AUTOSAR XML (schema 00048)
package /AUTOLIV/SoftwareComponents/BFE
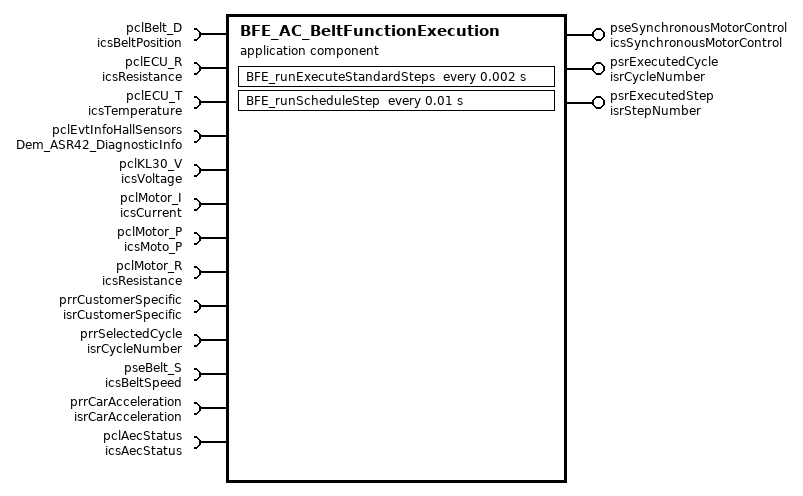
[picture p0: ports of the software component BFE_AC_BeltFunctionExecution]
  application sw component type BFE_AC_BeltFunctionExecution
    11 x require port:
      pclBelt_D: required-com-specs=[GetFromMinPos_deg, GetFromMinPos_mm, GetFromT0_deg, GetFromT0_mm, GetRange_deg, GetRange_mm], required-interface=icsBeltPosition
      pclECU_R: client-com-spec=Get, required-interface=icsResistance
      pclECU_T: required-com-specs=[GetFiltered, GetFiltered_deg, Init], required-interface=icsTemperature
      pclEvtInfoHallSensors: required-interface=Dem_ASR42_DiagnosticInfo
        required-com-specs:
          GetDTCOfEvent
          GetDebouncingOfEvent
          GetEventExtendedDataRecord
          GetEventExtendedDataRecordEx
          GetEventFailed
          GetEventFreezeFrameData
          GetEventFreezeFrameDataEx
          GetEventStatus
          GetEventTested
          GetFaultDetectionCounter
      pclKL30_V: required-com-specs=[Get, Get_100ms, Get_10ms, Get_20ms, Get_2ms], required-interface=icsVoltage
      pclMotor_I: required-com-specs=[ConvertCurrent_mAtoLSB, Get_A, Get_LSB, Get_mA], required-interface=icsCurrent
      pclMotor_P: required-com-specs=[GetPowerOrder, SetPowerOrder], required-interface=icsMoto_P
      pclMotor_R: client-com-spec=Get, required-interface=icsResistance
      prrCustomerSpecific: required-interface=isrCustomerSpecific
        required-com-specs:
          data-element=b8HardReleaseRequest
          data-element=b8IsCarCrankingActive
          data-element=b8IsCarCrashDetected
          data-element=b8IsTrigOffEventAllowed, init-value=constant-reference=APPLINIT_KB8_BOOLEAN_FALSE
          data-element=b8PreCrashRequestEnable
          data-element=u8BeltSlackStatus
          data-element=u8HapticRequest
          data-element=u8PreCrashRequest
          data-element=u8TriggerRequest
          data-element=b8SignalRelInhibition
      prrSelectedCycle: nonqueued-receiver-com-spec{data-element=u8CycleNumber, init-value=constant-reference=APPLINIT_KU8_CYCLE_NUMBER_NONE}, required-interface=isrCycleNumber
      pseBelt_S: required-com-specs=[GetSpeed_SingleEdge_deg_s, GetSpeed_deg_s, GetSpeed_mm_s], required-interface=icsBeltSpeed
    provide port pseSynchronousMotorControl: provided-interface=icsSynchronousMotorControl
      provided-com-specs:
        operation=ExecuteEmergencyBrakingSequence, queue-length=1
        operation=ExecuteHighPowerStep, queue-length=1
        operation=ResetMotorStageStatus, queue-length=1
    provide port psrExecutedCycle: nonqueued-sender-com-spec{data-element=u8CycleNumber, init-value=constant-reference=APPLINIT_KU8_CYCLE_NUMBER_NONE}, provided-interface=isrCycleNumber
    provide port psrExecutedStep: nonqueued-sender-com-spec{data-element=u8StepNumber, uses-end-to-end-protection=true, init-value=constant-reference=APPLINIT_KU8_STEP_NUMBER_NONE}, provided-interface=isrStepNumber
    require port prrCarAcceleration: nonqueued-receiver-com-spec{data-element=b8IsCarAccelerationLow, filter=data-filter-type=ALWAYS, init-value=constant-reference=APPLINIT_KB8_CAR_ACCEL_LOW_TRUE}, required-interface=isrCarAcceleration
    require port pclAecStatus: required-interface=icsAecStatus
      required-com-specs:
        SetAecEvent
        GetNumberOfImplementedAec
        GetAecStatus
        GetAecQualificationCount
        GetAecNvpBlockRecordingStatus
        GetAecGroupsStatus
        GetAecDeskillThrs
    behavior BFE_IB_BeltFunctionExecution: data-type-mapping=DataTypeMappingSet_PP4G
      exclusive area BFE_EXCLUSIVE_AREA
      operation invoked event BFE_evExecuteEmergencyBrakingSequence: start-on-event=BFE_runExecuteEmergencyBrakingSequence, operation=pseSynchronousMotorControl.ExecuteEmergencyBrakingSequence
      operation invoked event BFE_evExecuteHighPowerSteps: start-on-event=BFE_runExecuteHighPowerStep, operation=pseSynchronousMotorControl.ExecuteHighPowerStep
      timing event BFE_evExecuteStandardSteps: start-on-event=BFE_runExecuteStandardSteps, period=0.002
      operation invoked event BFE_evResetMotorStageStatus: start-on-event=BFE_runResetMotorStageStatus, operation=pseSynchronousMotorControl.ResetMotorStageStatus
      timing event BFE_evScheduleStep: start-on-event=BFE_runScheduleStep, period=0.01
      explicit-inter-runnable-variables:
        7 x data:
          s16MotorPowerOrder: sw-calibration-access=READ-ONLY, type=s16MotorPowerOrderType_Appl, init-value=constant-reference=APPLINIT_KS16_MOTOR_POWER_ORDER_ZERO
          s32FirstOrderValue: sw-calibration-access=READ-ONLY, type=s32OrderValueType_Appl, init-value=constant-reference=APPLINIT_KS32_ORDER_VALUE_ZERO
          s32OrderIncrementValue: sw-calibration-access=READ-ONLY, type=s32OrderValueType_Appl, init-value=constant-reference=APPLINIT_KS32_ORDER_VALUE_ZERO
          u16StepDuration: sw-calibration-access=READ-ONLY, type=u16StepDurationType_Appl, init-value=constant-reference=APPLINIT_KU16_STEP_DURATION_ZERO  # HP step need to know how long does the hp step last.
          u8MotorStageStatus: sw-calibration-access=READ-ONLY, type=u8MotorStageStatusType_Appl, init-value=constant-reference={short-label=ConstantValue4, constant=APPLINIT_KU8_MOTOR_STAGE_STATUS_ACTIVATION}  # To know if the motor stage is activated or not
          u8OrderType: sw-calibration-access=READ-ONLY, type=u8OrdersListType_Appl, init-value=constant-reference=APPLINIT_KU8_ORDERS_LIST_ZERO
          u8VelocityTarget: type=u8VelocityTargetType_Appl, init-value=constant-reference=APPLINIT_KU8_VELOCITY_TARGET_ZERO
      port-api-options:
        enable-take-address=false, error-handling=NO-TRANSFORMER-ERROR-HANDLING, indirect-api=false, port=pseSynchronousMotorControl
        enable-take-address=false, error-handling=NO-TRANSFORMER-ERROR-HANDLING, indirect-api=false, port=psrExecutedCycle
        enable-take-address=false, error-handling=NO-TRANSFORMER-ERROR-HANDLING, indirect-api=false, port=psrExecutedStep
        enable-take-address=false, error-handling=NO-TRANSFORMER-ERROR-HANDLING, indirect-api=false, port=prrSelectedCycle
      5 x runnable:
        BFE_runExecuteEmergencyBrakingSequence: can-be-invoked-concurrently=true
          read-local-variables:
            access Read_s16MotorPowerOrder: accessed-variable=s16MotorPowerOrder
            access Read_u8MotorStageStatus: accessed-variable=u8MotorStageStatus
          4 x sync call:
            SSCP_pclMotor_I_Get_mA: operation=pclMotor_I.Get_mA
            SSCP_pclMotor_P_SetPowerOrder: operation=pclMotor_P.SetPowerOrder
            scp_GetEventStatus: operation=pclEvtInfoHallSensors.GetEventStatus
            scp_GetSpeed_SingleEdge_deg_s: operation=pseBelt_S.GetSpeed_SingleEdge_deg_s
          written-local-variables:
            access WRITE_s16MotorPowerOrder: accessed-variable=s16MotorPowerOrder
            access WRITE_u8MotorStageStatus: accessed-variable=u8MotorStageStatus
        BFE_runExecuteHighPowerStep: can-be-invoked-concurrently=true
          read-local-variables:
            5 x access:
              Read_s16MotorPowerOrder: accessed-variable=s16MotorPowerOrder
              Read_s32FirstOrderValue: accessed-variable=s32FirstOrderValue
              Read_u16StepDuration: accessed-variable=u16StepDuration
              Read_u8MotorStageStatus: accessed-variable=u8MotorStageStatus
              Read_u8OrderType: accessed-variable=u8OrderType
          sync call SSCP_pclKL30_V_Get: operation=pclKL30_V.Get
          sync call SSCP_pclMotor_I_Get_mA: operation=pclMotor_I.Get_mA
          sync call SSCP_pclMotor_P_SetPowerOrder: operation=pclMotor_P.SetPowerOrder
          written-local-variables:
            access WRITE_s16MotorPowerOrder: accessed-variable=s16MotorPowerOrder
        BFE_runExecuteStandardSteps: can-enter-exclusive-area=BFE_EXCLUSIVE_AREA
          read-local-variables:
            6 x access:
              Read_s16MotorPowerOrder: accessed-variable=s16MotorPowerOrder
              Read_s32FirstOrderValue: accessed-variable=s32FirstOrderValue
              Read_s32OrderIncrementValue: accessed-variable=s32OrderIncrementValue
              Read_u8MotorStageStatus: accessed-variable=u8MotorStageStatus
              Read_u8OrderType: accessed-variable=u8OrderType
              Read_u8VelocityTarget: accessed-variable=u8VelocityTarget
          5 x sync call:
            SSCP_pclKL30_V_Get: operation=pclKL30_V.Get
            SSCP_pclKL30_V_Get_2ms: operation=pclKL30_V.Get_2ms
            SSCP_pclMotor_I_Get_A: operation=pclMotor_I.Get_A
            SSCP_pclMotor_I_Get_mA: operation=pclMotor_I.Get_mA
            SSCP_pclMotor_P_SetPowerOrder: operation=pclMotor_P.SetPowerOrder
          written-local-variables:
            access WRITE_s16MotorPowerOrder: accessed-variable=s16MotorPowerOrder
        BFE_runResetMotorStageStatus: can-enter-exclusive-area=BFE_EXCLUSIVE_AREA, can-be-invoked-concurrently=true
          written-local-variables:
            access WRITE_u8MotorStageStatus: accessed-variable=u8MotorStageStatus
        BFE_runScheduleStep
          data-receive-point-by-arguments:
            access DRP_prrSelect_u8CycleNumber: accessed-variable=prrSelectedCycle.u8CycleNumber
            access drparg_b8IsTrigOffEventAllow: accessed-variable=prrCustomerSpecific.b8IsTrigOffEventAllowed
            access REC_prrCarAcceleration_b8IsCarAccelerationLow: accessed-variable=prrCarAcceleration.b8IsCarAccelerationLow
          data-send-points:
            access DSP_psrExecut_u8CycleNumber: accessed-variable=psrExecutedCycle.u8CycleNumber
            access DSP_psrExecut_u8StepNumber: accessed-variable=psrExecutedStep.u8StepNumber
          read-local-variables:
            access Read_u8OrderType: accessed-variable=u8OrderType
            access Read_s16MotorPowerOrder: accessed-variable=s16MotorPowerOrder
            access Read_u8MotorStageStatus: accessed-variable=u8MotorStageStatus
          11 x sync call:
            SSCP_pclBelt_D_GetFromMinPos_mm: operation=pclBelt_D.GetFromMinPos_mm
            SSCP_pclBelt_D_GetFromT0_mm: operation=pclBelt_D.GetFromT0_mm
            SSCP_pclECU_R_Get: operation=pclECU_R.Get
            SSCP_pclECU_T_GetFiltered: operation=pclECU_T.GetFiltered
            SSCP_pclKL30_V_Get: operation=pclKL30_V.Get
            SSCP_pclMotor_I_Get_mA: operation=pclMotor_I.Get_mA
            SSCP_pclMotor_R_Get: operation=pclMotor_R.Get
            SSCP_pseBelt_S_GetSpeed_mm_s: operation=pseBelt_S.GetSpeed_mm_s
            scp_GetFiltered_deg: operation=pclECU_T.GetFiltered_deg
            scp_Get_10ms: operation=pclKL30_V.Get_10ms
            SC_pclAecStatus_GetAecStatus: operation=pclAecStatus.GetAecStatus
          written-local-variables:
            5 x access:
              WRITE_s32FirstOrderValue: accessed-variable=s32FirstOrderValue
              WRITE_s32OrderIncrementValue: accessed-variable=s32OrderIncrementValue
              WRITE_u16StepDuration: accessed-variable=u16StepDuration
              WRITE_u8VelocityTarget: accessed-variable=u8VelocityTarget
              WRITE_u8OrderType: accessed-variable=u8OrderType
  swc implementation BFE_AC_BeltFunctionExecution_Implementation: behavior=BFE_IB_BeltFunctionExecution
